VERSION "1.0"

NS_ :

BS_:

BU_: BMS VCU Engine

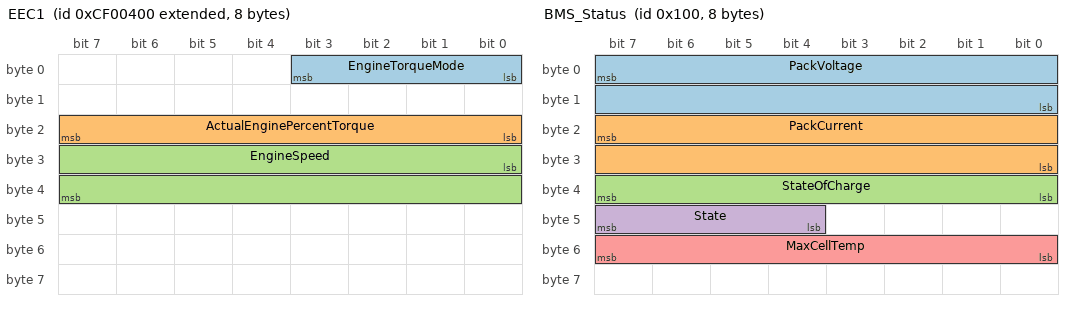
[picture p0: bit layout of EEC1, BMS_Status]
BO_ 2364539904 EEC1: 8 Engine
 SG_ EngineTorqueMode : 0|4@1+ (1,0) [0|15] "" VCU
 SG_ ActualEnginePercentTorque : 16|8@1+ (1,-125) [-125|125] "%" VCU
 SG_ EngineSpeed : 24|16@1+ (0.125,0) [0|8031.875] "rpm" VCU

BO_ 256 BMS_Status: 8 BMS
 SG_ PackVoltage : 7|16@0+ (0.1,0) [0|1000] "V" VCU
 SG_ PackCurrent : 23|16@0- (0.1,0) [-3276.8|3276.7] "A" VCU
 SG_ StateOfCharge : 39|8@0+ (0.5,0) [0|100] "%" VCU
 SG_ State : 47|4@0+ (1,0) [0|3] "" VCU
 SG_ MaxCellTemp : 55|8@0- (1,0) [-40|100] "degC" VCU

BO_ 257 BMS_Cells: 8 BMS
 SG_ CellGroup M : 0|8@1+ (1,0) [0|3] "" VCU
 SG_ Cell1 m0 : 8|16@1+ (0.001,0) [0|5] "V" VCU
 SG_ Cell2 m0 : 24|16@1+ (0.001,0) [0|5] "V" VCU
 SG_ Cell5 m1 : 8|16@1+ (0.001,0) [0|5] "V" VCU
 SG_ Cell6 m1 : 24|16@1+ (0.001,0) [0|5] "V" VCU

CM_ BO_ 256 "Battery pack status, every 100 ms.";
CM_ SG_ 256 PackCurrent "Positive when charging,
negative when driving.";
VAL_ 256 State 0 "Idle" 1 "Charging" 2 "Discharging" 3 "Fault" ;
